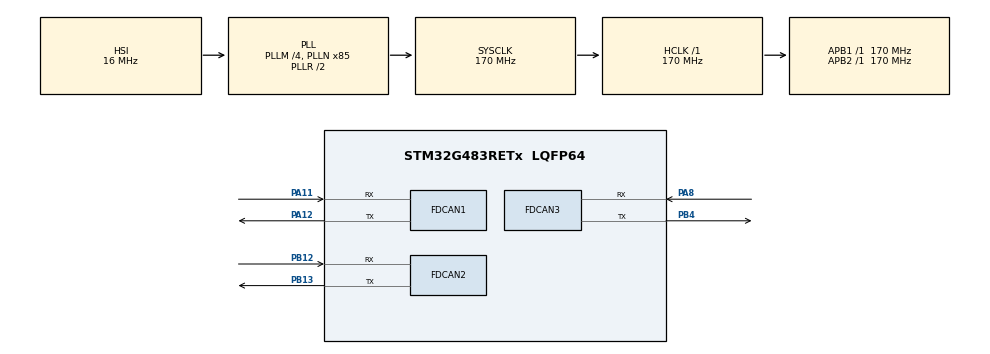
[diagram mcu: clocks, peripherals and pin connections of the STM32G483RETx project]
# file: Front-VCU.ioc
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FDCAN1.CalculateBaudRateNominal=3541666
FDCAN1.CalculateTimeBitNominal=282
FDCAN1.CalculateTimeQuantumNominal=94.11764705882354
FDCAN2.CalculateBaudRateNominal=3541666
FDCAN2.CalculateTimeBitNominal=282
FDCAN2.CalculateTimeQuantumNominal=94.11764705882354
FDCAN3.CalculateBaudRateNominal=3541666
FDCAN3.CalculateTimeBitNominal=282
FDCAN3.CalculateTimeQuantumNominal=94.11764705882354
FREERTOS.Tasks01=defaultTask,24,128,StartDefaultTask,Default,NULL,Dynamic,NULL,NULL
FREERTOS.configCHECK_FOR_STACK_OVERFLOW=2
FREERTOS.configENABLE_FPU=1
FREERTOS.configUSE_MALLOC_FAILED_HOOK=1
IWDG.Prescaler=IWDG_PRESCALER_64
Mcu.Family=STM32G4
Mcu.Name=STM32G483RETx
Mcu.Package=LQFP64
NVIC.PriorityGroup=NVIC_PRIORITYGROUP_4
NVIC.TIM6_DAC_IRQn=true\:15\:0\:false\:false\:true\:false\:false\:true\:true
NVIC.TimeBase=TIM6_DAC_IRQn
NVIC.TimeBaseIP=TIM6
PA11.Mode=FDCAN_Activate
PA11.Signal=FDCAN1_RX
PA12.Mode=FDCAN_Activate
PA12.Signal=FDCAN1_TX
PA13.Mode=Trace_Asynchronous_SW
PA13.Signal=SYS_JTMS-SWDIO
PA14.Mode=Trace_Asynchronous_SW
PA14.Signal=SYS_JTCK-SWCLK
PA8.Mode=FDCAN_Activate
PA8.Signal=FDCAN3_RX
PB12.Mode=FDCAN_Activate
PB12.Signal=FDCAN2_RX
PB13.Mode=FDCAN_Activate
PB13.Signal=FDCAN2_TX
PB3.Mode=Trace_Asynchronous_SW
PB3.Signal=SYS_JTDO-SWO
PB4.Mode=FDCAN_Activate
PB4.Signal=FDCAN3_TX
ProjectManager.HeapSize=0x200
ProjectManager.StackSize=0x400
ProjectManager.TargetToolchain=Makefile
RCC.ADC12Freq_Value=170000000
RCC.ADC345Freq_Value=170000000
RCC.AHBFreq_Value=170000000
RCC.APB1Freq_Value=170000000
RCC.APB1TimFreq_Value=170000000
RCC.APB2Freq_Value=170000000
RCC.APB2TimFreq_Value=170000000
RCC.CortexFreq_Value=170000000
RCC.EXTERNAL_CLOCK_VALUE=12288000
RCC.HCLKFreq_Value=170000000
RCC.HSE_VALUE=8000000
RCC.HSI48_VALUE=48000000
RCC.HSI_VALUE=16000000
RCC.LSE_VALUE=32768
RCC.PLLM=RCC_PLLM_DIV4
RCC.PLLN=85
RCC.SYSCLKFreq_VALUE=170000000
RCC.SYSCLKSource=RCC_SYSCLKSOURCE_PLLCLK
RCC.USBFreq_Value=170000000
RCC.VCOOutputFreq_Value=340000000
VP_FREERTOS_VS_CMSIS_V2.Mode=CMSIS_V2
VP_IWDG_VS_IWDG.Mode=IWDG_Activate
VP_SYS_VS_DBSignals.Mode=DisableDeadBatterySignals
VP_SYS_VS_tim6.Mode=TIM6
board=custom

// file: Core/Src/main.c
/* USER CODE BEGIN Header */
/**
  ******************************************************************************
  * @file           : main.c
  * @brief          : Main program body
  ******************************************************************************
  * @attention
  *
  * Copyright (c) 2026 STMicroelectronics.
  * All rights reserved.
  *
  * This software is licensed under terms that can be found in the LICENSE file
  * in the root directory of this software component.
  * If no LICENSE file comes with this software, it is provided AS-IS.
  *
  ******************************************************************************
  */
/* USER CODE END Header */
#include "main.h"
#include "cmsis_os.h"

/* USER CODE BEGIN Includes */
#include "user_threads.h"
/* USER CODE END Includes */

FDCAN_HandleTypeDef hfdcan1;
FDCAN_HandleTypeDef hfdcan2;
FDCAN_HandleTypeDef hfdcan3;

IWDG_HandleTypeDef hiwdg;

/* Definitions for defaultTask */
osThreadId_t defaultTaskHandle;
const osThreadAttr_t defaultTask_attributes = {
  .name = "defaultTask",
  .priority = (osPriority_t) osPriorityNormal,
  .stack_size = 128 * 4
};

void SystemClock_Config(void);
static void MX_GPIO_Init(void);
static void MX_FDCAN1_Init(void);
static void MX_FDCAN2_Init(void);
static void MX_FDCAN3_Init(void);
static void MX_IWDG_Init(void);
void StartDefaultTask(void *argument);

int main(void)
{

  /* MCU Configuration--------------------------------------------------------*/

  /* Reset of all peripherals, Initializes the Flash interface and the Systick. */
  HAL_Init();

  /* Configure the system clock */
  SystemClock_Config();

  /* Initialize all configured peripherals */
  MX_GPIO_Init();
  MX_FDCAN1_Init();
  MX_FDCAN2_Init();
  MX_FDCAN3_Init();
  MX_IWDG_Init();

  /* Init scheduler */
  osKernelInitialize();

  /* Create the thread(s) */
  /* creation of defaultTask */
  defaultTaskHandle = osThreadNew(StartDefaultTask, NULL, &defaultTask_attributes);

  /* Start scheduler */
  osKernelStart();

  /* We should never get here as control is now taken by the scheduler */

  /* Infinite loop */
  while (1)
  {

  }
}

void SystemClock_Config(void)
{
  RCC_OscInitTypeDef RCC_OscInitStruct = {0};
  RCC_ClkInitTypeDef RCC_ClkInitStruct = {0};

  /** Configure the main internal regulator output voltage
  */
  HAL_PWREx_ControlVoltageScaling(PWR_REGULATOR_VOLTAGE_SCALE1_BOOST);

  /** Initializes the RCC Oscillators according to the specified parameters
  * in the RCC_OscInitTypeDef structure.
  */
  RCC_OscInitStruct.OscillatorType = RCC_OSCILLATORTYPE_HSI|RCC_OSCILLATORTYPE_LSI;
  RCC_OscInitStruct.HSIState = RCC_HSI_ON;
  RCC_OscInitStruct.HSICalibrationValue = RCC_HSICALIBRATION_DEFAULT;
  RCC_OscInitStruct.LSIState = RCC_LSI_ON;
  RCC_OscInitStruct.PLL.PLLState = RCC_PLL_ON;
  RCC_OscInitStruct.PLL.PLLSource = RCC_PLLSOURCE_HSI;
  RCC_OscInitStruct.PLL.PLLM = RCC_PLLM_DIV4;
  RCC_OscInitStruct.PLL.PLLN = 85;
  RCC_OscInitStruct.PLL.PLLP = RCC_PLLP_DIV2;
  RCC_OscInitStruct.PLL.PLLQ = RCC_PLLQ_DIV2;
  RCC_OscInitStruct.PLL.PLLR = RCC_PLLR_DIV2;
  if (HAL_RCC_OscConfig(&RCC_OscInitStruct) != HAL_OK)
  {
    Error_Handler();
  }

  /** Initializes the CPU, AHB and APB buses clocks
  */
  RCC_ClkInitStruct.ClockType = RCC_CLOCKTYPE_HCLK|RCC_CLOCKTYPE_SYSCLK
                              |RCC_CLOCKTYPE_PCLK1|RCC_CLOCKTYPE_PCLK2;
  RCC_ClkInitStruct.SYSCLKSource = RCC_SYSCLKSOURCE_PLLCLK;
  RCC_ClkInitStruct.AHBCLKDivider = RCC_SYSCLK_DIV1;
  RCC_ClkInitStruct.APB1CLKDivider = RCC_HCLK_DIV1;
  RCC_ClkInitStruct.APB2CLKDivider = RCC_HCLK_DIV1;

  if (HAL_RCC_ClockConfig(&RCC_ClkInitStruct, FLASH_LATENCY_4) != HAL_OK)
  {
    Error_Handler();
  }
}

static void MX_FDCAN1_Init(void)
{

  hfdcan1.Instance = FDCAN1;
  hfdcan1.Init.ClockDivider = FDCAN_CLOCK_DIV1;
  hfdcan1.Init.FrameFormat = FDCAN_FRAME_CLASSIC;
  hfdcan1.Init.Mode = FDCAN_MODE_NORMAL;
  hfdcan1.Init.AutoRetransmission = DISABLE;
  hfdcan1.Init.TransmitPause = DISABLE;
  hfdcan1.Init.ProtocolException = DISABLE;
  hfdcan1.Init.NominalPrescaler = 16;
  hfdcan1.Init.NominalSyncJumpWidth = 1;
  hfdcan1.Init.NominalTimeSeg1 = 1;
  hfdcan1.Init.NominalTimeSeg2 = 1;
  hfdcan1.Init.DataPrescaler = 1;
  hfdcan1.Init.DataSyncJumpWidth = 1;
  hfdcan1.Init.DataTimeSeg1 = 1;
  hfdcan1.Init.DataTimeSeg2 = 1;
  hfdcan1.Init.StdFiltersNbr = 0;
  hfdcan1.Init.ExtFiltersNbr = 0;
  hfdcan1.Init.TxFifoQueueMode = FDCAN_TX_FIFO_OPERATION;
  if (HAL_FDCAN_Init(&hfdcan1) != HAL_OK)
  {
    Error_Handler();
  }

}

static void MX_FDCAN2_Init(void)
{

  hfdcan2.Instance = FDCAN2;
  hfdcan2.Init.ClockDivider = FDCAN_CLOCK_DIV1;
  hfdcan2.Init.FrameFormat = FDCAN_FRAME_CLASSIC;
  hfdcan2.Init.Mode = FDCAN_MODE_NORMAL;
  hfdcan2.Init.AutoRetransmission = DISABLE;
  hfdcan2.Init.TransmitPause = DISABLE;
  hfdcan2.Init.ProtocolException = DISABLE;
  hfdcan2.Init.NominalPrescaler = 16;
  hfdcan2.Init.NominalSyncJumpWidth = 1;
  hfdcan2.Init.NominalTimeSeg1 = 1;
  hfdcan2.Init.NominalTimeSeg2 = 1;
  hfdcan2.Init.DataPrescaler = 1;
  hfdcan2.Init.DataSyncJumpWidth = 1;
  hfdcan2.Init.DataTimeSeg1 = 1;
  hfdcan2.Init.DataTimeSeg2 = 1;
  hfdcan2.Init.StdFiltersNbr = 0;
  hfdcan2.Init.ExtFiltersNbr = 0;
  hfdcan2.Init.TxFifoQueueMode = FDCAN_TX_FIFO_OPERATION;
  if (HAL_FDCAN_Init(&hfdcan2) != HAL_OK)
  {
    Error_Handler();
  }

}

static void MX_FDCAN3_Init(void)
{

  hfdcan3.Instance = FDCAN3;
  hfdcan3.Init.ClockDivider = FDCAN_CLOCK_DIV1;
  hfdcan3.Init.FrameFormat = FDCAN_FRAME_CLASSIC;
  hfdcan3.Init.Mode = FDCAN_MODE_NORMAL;
  hfdcan3.Init.AutoRetransmission = DISABLE;
  hfdcan3.Init.TransmitPause = DISABLE;
  hfdcan3.Init.ProtocolException = DISABLE;
  hfdcan3.Init.NominalPrescaler = 16;
  hfdcan3.Init.NominalSyncJumpWidth = 1;
  hfdcan3.Init.NominalTimeSeg1 = 1;
  hfdcan3.Init.NominalTimeSeg2 = 1;
  hfdcan3.Init.DataPrescaler = 1;
  hfdcan3.Init.DataSyncJumpWidth = 1;
  hfdcan3.Init.DataTimeSeg1 = 1;
  hfdcan3.Init.DataTimeSeg2 = 1;
  hfdcan3.Init.StdFiltersNbr = 0;
  hfdcan3.Init.ExtFiltersNbr = 0;
  hfdcan3.Init.TxFifoQueueMode = FDCAN_TX_FIFO_OPERATION;
  if (HAL_FDCAN_Init(&hfdcan3) != HAL_OK)
  {
    Error_Handler();
  }

}

static void MX_IWDG_Init(void)
{

  hiwdg.Instance = IWDG;
  hiwdg.Init.Prescaler = IWDG_PRESCALER_64;
  hiwdg.Init.Window = 4095;
  hiwdg.Init.Reload = 4095;
  if (HAL_IWDG_Init(&hiwdg) != HAL_OK)
  {
    Error_Handler();
  }

}

static void MX_GPIO_Init(void)
{

  /* GPIO Ports Clock Enable */
  __HAL_RCC_GPIOB_CLK_ENABLE();
  __HAL_RCC_GPIOA_CLK_ENABLE();

}

void StartDefaultTask(void *argument)
{
  /* USER CODE BEGIN 5 */
  /* default task is infinite loop */
  userDefaultTask(argument);
  /* USER CODE END 5 */
}

void HAL_TIM_PeriodElapsedCallback(TIM_HandleTypeDef *htim)
{
  if (htim->Instance == TIM6)
  {
    HAL_IncTick();
  }
}

void Error_Handler(void)
{
  __disable_irq();
  while (1)
  {
  }
}
